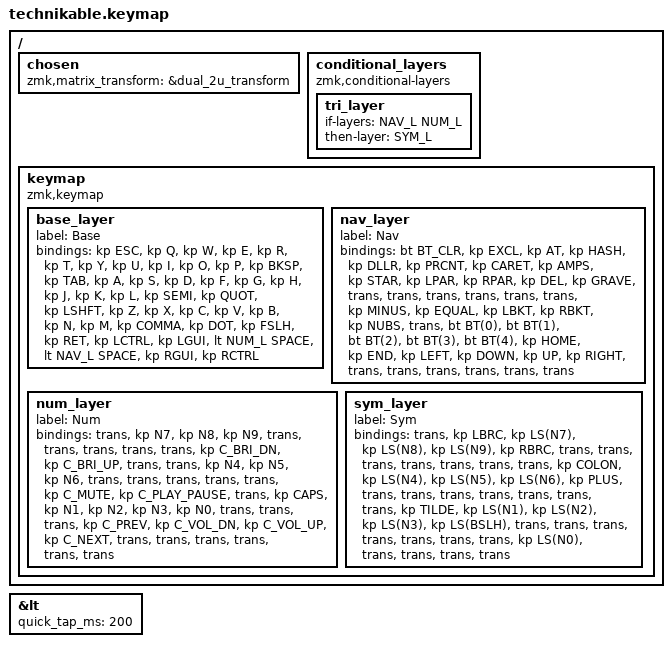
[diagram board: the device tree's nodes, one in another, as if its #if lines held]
/*
 * Copyright (c) 2022 Pete Johanson
 *
 * SPDX-License-Identifier: MIT
 */

#include <behaviors.dtsi>
#include <dt-bindings/zmk/keys.h>
#include <dt-bindings/zmk/bt.h>
#include <dt-bindings/zmk/outputs.h>

#define QWERTY_BASE 1

#define TBLE_ORTHO   true
// #define TBLE_MIT     true
// #define TBLE_DUAL_2U true

#define BAS_L 0
#define NAV_L 1
#define NUM_L 2
#define SYM_L 3

// Using layer taps on thumbs, having quick tap as well helps w/ repeating space/backspace
&lt { quick_tap_ms = <200>; };

#define BT(n) BT_SEL n

/ {
    chosen {
       zmk,matrix_transform =
#ifdef TBLE_DUAL_2U
                       &dual_2u_transform;
#elif defined(TBLE_MIT)
                       &mit_transform;
#else
                       &ortho_transform;
#endif
    };

    conditional_layers {
        compatible = "zmk,conditional-layers";
	tri_layer {
	    if-layers = <NAV_L NUM_L>;
	    then-layer = <SYM_L>;
	};
    };

    keymap {
        compatible = "zmk,keymap";

        base_layer {
            label = "Base";
            bindings = <
#ifdef QWERTY_BASE
 &kp ESC    &kp Q      &kp W      &kp E       &kp R          &kp T          &kp Y            &kp U          &kp I       &kp O      &kp P         &kp BKSP
 &kp TAB    &kp A      &kp S      &kp D       &kp F          &kp G          &kp H            &kp J          &kp K       &kp L      &kp SEMI      &kp QUOT
 &kp LSHFT  &kp Z      &kp X      &kp C       &kp V          &kp B          &kp N            &kp M          &kp COMMA   &kp DOT    &kp FSLH      &kp RET
#else
 &kp ESC    &kp Q      &kp W      &kp E       &kp R          &kp T          &kp Y            &kp U          &kp I       &kp O      &kp P         &kp BKSP
 &kp TAB    &kp A      &kp S      &kp D       &kp F          &kp G          &kp H            &kp J          &kp K       &kp L      &kp SEMI      &kp QUOT
 &kp LSHFT  &kp Z      &kp X      &kp C       &kp V          &kp B          &kp N            &kp M          &kp COMMA   &kp DOT    &kp FSLH      &kp RET
#endif
#ifdef TBLE_DUAL_2U
                       &kp LCTRL  &kp LGUI      &lt NUM_L SPACE                &lt NAV_L SPACE              &kp RGUI    &kp RCTRL
#elif defined(TBLE_MIT)
                       &kp LCTRL  &kp LGUI    &mo NUM_L          &kp SPACE                   &mo NAV_L      &kp RGUI    &kp RCTRL
#else
                       &kp LCTRL  &kp LGUI    &mo NUM_L      &kp SPACE      &kp BKSP        &mo NAV_L      &kp RGUI    &kp RCTRL
#endif
            >;
        };

        nav_layer {
            label = "Nav";
            bindings = <
&bt BT_CLR &kp EXCL     &kp AT     &kp HASH      &kp DLLR    &kp PRCNT    &kp CARET  &kp AMPS     &kp STAR     &kp LPAR   &kp RPAR   &kp DEL
&kp GRAVE  &trans       &trans     &trans        &trans      &trans       &trans     &kp MINUS    &kp EQUAL    &kp LBKT   &kp RBKT   &kp NUBS
&trans     &bt BT(0)    &bt BT(1)  &bt BT(2)     &bt BT(3)   &bt BT(4)    &kp HOME   &kp END      &kp LEFT     &kp DOWN   &kp UP     &kp RIGHT
#ifdef TBLE_DUAL_2U
                      &trans     &trans              &trans                    &trans       &trans         &trans
#elif defined(TBLE_MIT)
                      &trans     &trans      &trans                &trans             &trans      &trans   &trans
#else
                      &trans     &trans      &trans          &trans       &trans    &trans  &trans         &trans
#endif
            >;
        };

        num_layer {
            label = "Num";
            bindings = <
&trans     &kp N7     &kp N8      &kp N9    &trans   &trans    &trans      &trans       &trans       &kp C_BRI_DN  &kp C_BRI_UP      &trans
&trans     &kp N4     &kp N5      &kp N6    &trans   &trans    &trans      &trans       &trans       &kp C_MUTE    &kp C_PLAY_PAUSE  &trans
&kp CAPS   &kp N1     &kp N2      &kp N3    &kp N0   &trans    &trans      &trans       &kp C_PREV   &kp C_VOL_DN  &kp C_VOL_UP      &kp C_NEXT
#ifdef TBLE_DUAL_2U
                     &trans     &trans              &trans                 &trans            &trans         &trans
#elif defined(TBLE_MIT)
                     &trans     &trans      &trans           &trans            &trans        &trans      &trans
#else
                     &trans     &trans      &trans    &trans         &trans     &trans        &trans      &trans
#endif
            >;
        };

        sym_layer {
            label = "Sym";
            bindings = <
&trans     &kp LBRC   &kp LS(N7) &kp LS(N8)  &kp LS(N9)   &kp RBRC     &trans     &trans    &trans       &trans       &trans     &trans
&trans     &kp COLON  &kp LS(N4) &kp LS(N5)  &kp LS(N6)   &kp PLUS     &trans     &trans    &trans       &trans       &trans     &trans
&trans     &kp TILDE  &kp LS(N1) &kp LS(N2)  &kp LS(N3)   &kp LS(BSLH) &trans     &trans    &trans       &trans       &trans     &trans
#ifdef TBLE_DUAL_2U
                      &trans     &kp LS(N0)              &trans                    &trans       &trans         &trans
#elif defined(TBLE_MIT)
                      &trans     &kp LS(N0)      &trans                &trans             &trans      &trans   &trans
#else
                      &trans     &kp LS(N0)      &trans          &trans       &trans    &trans  &trans         &trans
#endif
            >;
        };

    };
};

